# STM32H733 register map
File version: 1.8
CPU: CM7 r0p1, little endian, MPU, FPU, 4 interrupt priority bits
Registers are 32-bit, read-write, reset 0x0 unless marked. A register's access mark holds for its fields unless they carry their own. Offsets are from the block's base; [hi:lo] are bit positions; {n}, {i} and the like mark numbered series; 'fields as' and 'values as' point back to an identical list.

## HASH — HASH address block description
Base 0x48021400
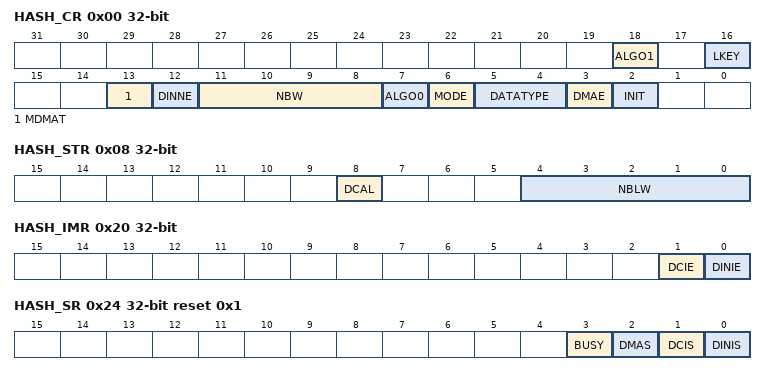
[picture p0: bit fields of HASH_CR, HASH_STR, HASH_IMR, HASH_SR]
0x00 HASH_CR — HASH control register
  [18] ALGO1 — Algorithm selection
  [16] LKEY — Long key selection
  [13] MDMAT — Multiple DMA transfers
  [12] DINNE ro — DIN not empty
  [11:8] NBW ro — Number of words already pushed
  [7] ALGO0 — Algorithm selection
  [6] MODE — Mode selection
  [5:4] DATATYPE — Data type selection
  [3] DMAE — DMA enable
  [2] INIT — Initialize message digest calculation
0x04 HASH_DIN — HASH data input register
  [31:0] DATAIN — Data input
0x08 HASH_STR — HASH start register
  [8] DCAL — Digest calculation
  [4:0] NBLW — Number of valid bits in the last word
{0xC+4i} HASH_HRA{i} ro (i=0..4) — HASH aliased digest register {i}
  [31:0] H{i} — Hash data x
0x20 HASH_IMR — HASH interrupt enable register
  [1] DCIE — Digest calculation completion interrupt enable
  [0] DINIE — Data input interrupt enable
0x24 HASH_SR reset 0x1 — HASH status register
  [3] BUSY ro — Busy bit
  [2] DMAS ro — DMA Status
  [1] DCIS — Digest calculation completion interrupt status
  [0] DINIS — Data input interrupt status
{0xF8+4i} HASH_CSR{i} (i=0..53) — HASH context swap register {i}
  [31:0] CS{i} — Context swap x
{0x310+4i} HASH_HR{i} ro (i=0..4) — HASH digest register {i}
  [31:0] H{i} — Hash data x
{0x310+4i} HASH_HR{i} ro (i=5..7) — HASH supplementary digest register {i}
  [31:0] H{i} — Hash data x

## MDIOS — Management data input/output slave
Base 0x40009400
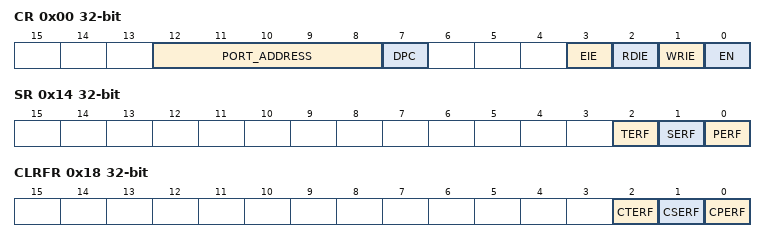
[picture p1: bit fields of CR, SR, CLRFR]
0x00 CR — MDIOS configuration register
  [12:8] PORT_ADDRESS — Slaves's address
  [7] DPC — Disable Preamble Check
  [3] EIE — Error interrupt enable
  [2] RDIE — Register Read Interrupt Enable
  [1] WRIE — Register write interrupt enable
  [0] EN — Peripheral enable
0x04 WRFR ro — MDIOS write flag register
  [31:0] WRF — Write flags for MDIO registers 0 to 31
0x08 CWRFR — MDIOS clear write flag register
  [31:0] CWRF — Clear the write flag
0x0C RDFR ro — MDIOS read flag register
  [31:0] RDF — Read flags for MDIO registers 0 to 31
0x10 CRDFR — MDIOS clear read flag register
  [31:0] CRDF — Clear the read flag
0x14 SR ro — MDIOS status register
  [2] TERF — Turnaround error flag
  [1] SERF — Start error flag
  [0] PERF — Preamble error flag
0x18 CLRFR — MDIOS clear flag register
  [2] CTERF — Clear the turnaround error flag
  [1] CSERF — Clear the start error flag
  [0] CPERF — Clear the preamble error flag
{0x1C+4i} DINR{i} ro (i=0..31) — MDIOS input data register {i}
  [15:0] DIN{i} — Input data received from MDIO Master during write frames
{0x9C+4i} DOUTR{i} (i=0..31) — MDIOS output data register {i}
  [15:0] DOUT{i} — Output data sent to MDIO Master during read frames

## OPAMP — Operational amplifiers
Base 0x40009000
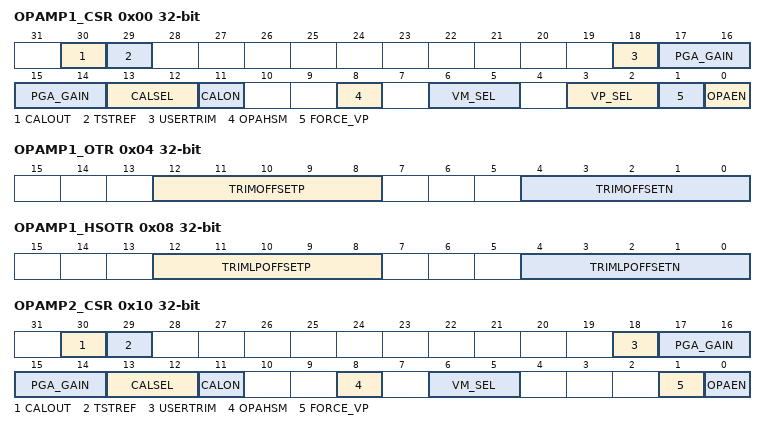
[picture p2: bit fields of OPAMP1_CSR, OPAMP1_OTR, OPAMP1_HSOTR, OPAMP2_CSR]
0x00 OPAMP1_CSR — OPAMP1 control/status register
  [30] CALOUT — Operational amplifier calibration output
  [29] TSTREF — OPAMP calibration reference voltage output control (reserved for test)
  [18] USERTRIM — User trimming enable
  [17:14] PGA_GAIN — allows to switch from AOP offset trimmed values to AOP offset
  [13:12] CALSEL — Calibration selection
  [11] CALON — Calibration mode enabled
  [8] OPAHSM — Operational amplifier high-speed mode
  [6:5] VM_SEL — Inverting input selection
  [3:2] VP_SEL — Operational amplifier PGA mode
  [1] FORCE_VP — Force internal reference on VP (reserved for test
  [0] OPAEN — Operational amplifier Enable
0x04 OPAMP1_OTR — OPAMP1 offset trimming register in normal mode
  [12:8] TRIMOFFSETP — Trim for PMOS differential pairs
  [4:0] TRIMOFFSETN — Trim for NMOS differential pairs
0x08 OPAMP1_HSOTR — OPAMP1 offset trimming register in low-power mode
  [12:8] TRIMLPOFFSETP — Trim for PMOS differential pairs
  [4:0] TRIMLPOFFSETN — Trim for NMOS differential pairs
0x10 OPAMP2_CSR — OPAMP2 control/status register
  [30] CALOUT — Operational amplifier calibration output
  [29] TSTREF — OPAMP calibration reference voltage output control (reserved for test)
  [18] USERTRIM — User trimming enable
  [17:14] PGA_GAIN — Operational amplifier Programmable amplifier gain value
  [13:12] CALSEL — Calibration selection
  [11] CALON — Calibration mode enabled
  [8] OPAHSM — Operational amplifier high-speed mode
  [6:5] VM_SEL — Inverting input selection
  [1] FORCE_VP — Force internal reference on VP (reserved for test)
  [0] OPAEN — Operational amplifier Enable
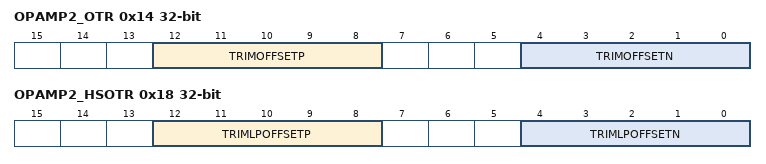
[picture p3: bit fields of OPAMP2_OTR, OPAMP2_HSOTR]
0x14 OPAMP2_OTR — OPAMP2 offset trimming register in normal mode
  fields as OPAMP1_OTR
0x18 OPAMP2_HSOTR — OPAMP2 offset trimming register in low-power mode
  fields as OPAMP1_HSOTR
